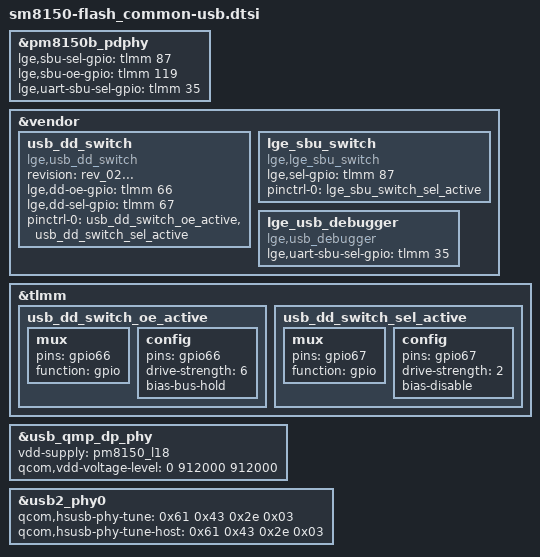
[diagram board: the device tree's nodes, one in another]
/*
 * Copyright (c) 2018, The Linux Foundation. All rights reserved.
 *
 * This program is free software; you can redistribute it and/or modify
 * it under the terms of the GNU General Public License version 2 and
 * only version 2 as published by the Free Software Foundation.
 *
 * This program is distributed in the hope that it will be useful,
 * but WITHOUT ANY WARRANTY; without even the implied warranty of
 * MERCHANTABILITY or FITNESS FOR A PARTICULAR PURPOSE.  See the
 * GNU General Public License for more details.
 */

#include "../../sm8150_common/sm8150_common-usb.dtsi"

&pm8150b_pdphy {
	lge,sbu-sel-gpio = <&tlmm 87 0>;
	lge,sbu-oe-gpio = <&tlmm 119 0>;
	lge,uart-sbu-sel-gpio = <&tlmm 35 0>;
};

/*
 * LGE USB Type-C Dual Display Switch driver
 * Flash H/W rev_o.2 or later is supported.
 */
&vendor {
      usb_dd_switch: usb_dd_switch {
              compatible = "lge,usb_dd_switch";
              revision = "rev_02...";
              lge,dd-oe-gpio = <&tlmm 66 0>;
              lge,dd-sel-gpio = <&tlmm 67 0>;
              pinctrl-names = "default";
              pinctrl-0 = <&usb_dd_switch_oe_active &usb_dd_switch_sel_active>;
      };
};

&tlmm {
      usb_dd_switch_oe_active: usb_dd_switch_oe_active {
              mux {
                      pins = "gpio66";
                      function = "gpio";
              };

              config {
                      pins = "gpio66";
                      drive-strength = <6>;
                      bias-bus-hold;
              };
      };

      usb_dd_switch_sel_active: usb_dd_switch_sel_active {
              mux {
                      pins = "gpio67";
                      function = "gpio";
              };

              config {
                      pins = "gpio67";
                      drive-strength = <2>;
                      bias-disable;
              };
      };
};

&usb_qmp_dp_phy {
	vdd-supply = <&pm8150_l18>;
	qcom,vdd-voltage-level = <0 912000 912000>;
};

&usb2_phy0 {
	qcom,hsusb-phy-tune = <0x61 0x43 0x2e 0x03>;
	qcom,hsusb-phy-tune-host = <0x61 0x43 0x2e 0x03>;
};

/*
 * LGE USB Type-C CC/SBU Protection Switch driver
 */
&vendor {
	lge_sbu_switch: lge_sbu_switch {
		compatible = "lge,lge_sbu_switch";

		lge,sel-gpio = <&tlmm 87 0>;
		/* lge,ovp-gpio */

		pinctrl-names = "default";
		pinctrl-0 = <&lge_sbu_switch_sel_active /* &lge_sbu_switch_ovp_active */>;
	};
};

/*
 * LGE USB UART debugger driver
 */
&vendor {
	lge_usb_debugger: lge_usb_debugger {
		compatible = "lge,usb_debugger";

		lge,uart-sbu-sel-gpio = <&tlmm 35 0>;
	};
};
